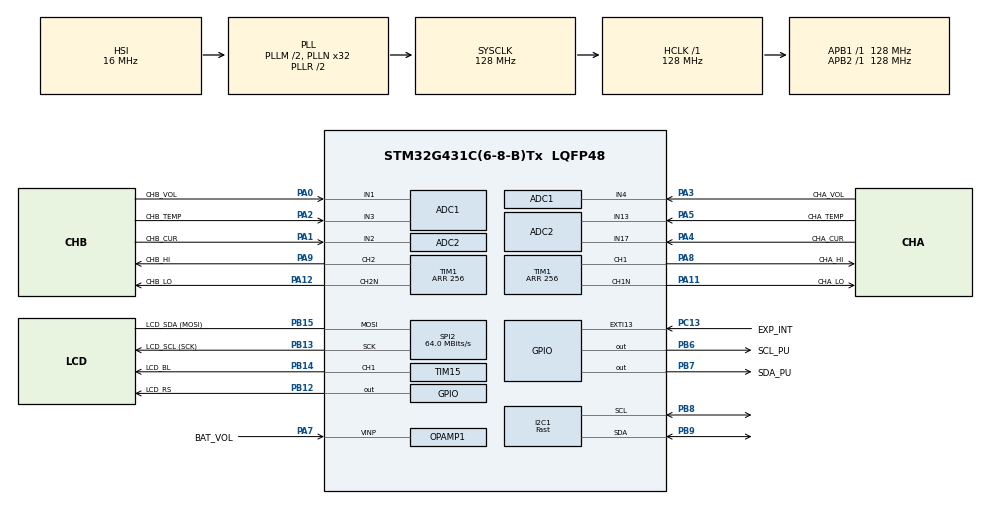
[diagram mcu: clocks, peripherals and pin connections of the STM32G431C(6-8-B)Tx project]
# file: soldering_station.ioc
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Mcu.Family=STM32G4
RCC.CortexFreq_Value=128000000
I2C1.I2C_Speed_Mode=I2C_Fast
ADC2.SamplingTime-1\#ChannelRegularConversion=ADC_SAMPLETIME_2CYCLES_5
SPI2.VirtualType=VM_MASTER
ADC1.ContinuousConvMode=ENABLE
ADC2.Channel-0\#ChannelRegularConversion=ADC_CHANNEL_17
Dma.ADC1.0.Polarity=HAL_DMAMUX_REQ_GEN_RISING
Dma.ADC2.1.SyncRequestNumber=1
PB14.GPIO_Label=LCD_BL
PA0.GPIO_Label=CHB_VOL
PA11.Mode=PWM Generation1 CH1 CH1N
Dma.I2C1_RX.2.MemDataAlignment=DMA_MDATAALIGN_BYTE
PB6.GPIO_Label=SCL_PU
PC13.GPIO_Label=EXP_INT
PB13.GPIO_Label=LCD_SCL (SCK)
PB13.Signal=SPI2_SCK
PB15.Signal=SPI2_MOSI
RCC.SYSCLKSource=RCC_SYSCLKSOURCE_PLLCLK
ProjectManager.StackSize=0x400
NVIC.DMA1_Channel3_IRQn=true\:0\:0\:false\:false\:true\:false\:true
PA12.Signal=TIM1_CH2N
PA4.Mode=IN17-Single-Ended
Dma.I2C1_RX.2.PeriphDataAlignment=DMA_PDATAALIGN_BYTE
ADC2.DMAContinuousRequests=ENABLE
ADC1.Mode=ADC_DUALMODE_REGSIMULT
ADC1.Channel-3\#ChannelRegularConversion=ADC_CHANNEL_1
Dma.ADC2.1.SyncEnable=DISABLE
RCC.HCLKFreq_Value=128000000
RCC.APB2TimFreq_Value=128000000
PB6.Signal=GPIO_Output
Dma.ADC1.0.Direction=DMA_PERIPH_TO_MEMORY
Dma.I2C1_RX.2.SyncPolarity=HAL_DMAMUX_SYNC_NO_EVENT
Dma.ADC1.0.MemDataAlignment=DMA_MDATAALIGN_HALFWORD
RCC.AHBFreq_Value=128000000
SPI2.BaudRatePrescaler=SPI_BAUDRATEPRESCALER_2
VREF+.Signal=VREFBUF_OUT
RCC.HSE_VALUE=8000000
PB3.Mode=JTAG_5_pins
PA15.Mode=JTAG_5_pins
RCC.ADC12Freq_Value=32000000
Dma.I2C1_RX.2.Mode=DMA_NORMAL
PB12.GPIO_Label=LCD_RS
Dma.ADC2.1.RequestNumber=1
Dma.ADC2.1.SyncPolarity=HAL_DMAMUX_SYNC_NO_EVENT
Dma.ADC2.1.Instance=DMA1_Channel2
PB4.Mode=JTAG_5_pins
PA14.Mode=JTAG_5_pins
Dma.ADC1.0.PeriphInc=DMA_PINC_DISABLE
TIM1.DeadTime=6
Dma.ADC2.1.Polarity=HAL_DMAMUX_REQ_GEN_RISING
NVIC.TIM2_IRQn=true\:0\:0\:false\:false\:true\:false\:true
PA0.Mode=IN1-Single-Ended
ADC2.DMAAccessModeView=DISABLED
PC13.GPIO_PuPd=GPIO_PULLUP
SPI2.CalculateBaudRate=64.0 MBits/s
VP_SYS_VS_DBSignals.Mode=DisableDeadBatterySignals
PB7.Signal=GPIO_Output
PA8.Signal=S_TIM1_CH1
Dma.ADC2.1.PeriphInc=DMA_PINC_DISABLE
Dma.I2C1_RX.2.Priority=DMA_PRIORITY_LOW
VREF+.GPIO_Label=VREF
VP_TIM1_VS_ClockSourceINT.Mode=Internal
PA0.Signal=ADC1_IN1
PB7.GPIO_Label=SDA_PU
Mcu.Package=LQFP48
PB9.Signal=I2C1_SDA
VP_SYS_VS_tim2.Mode=TIM2
NVIC.TimeBase=TIM2_IRQn
SPI2.Mode=SPI_MODE_MASTER
ADC1.OversamplingMode=DISABLE
Dma.I2C1_RX.2.PeriphInc=DMA_PINC_DISABLE
ADC2.Overrun=ADC_OVR_DATA_PRESERVED
Dma.I2C1_RX.2.Instance=DMA1_Channel3
PA2.GPIO_Label=CHB_TEMP
ADC2.Channel-1\#ChannelRegularConversion=ADC_CHANNEL_2
NVIC.TimeBaseIP=TIM2
PA15.Signal=SYS_JTDI
ADC1.OffsetNumber-1\#ChannelRegularConversion=ADC_OFFSET_NONE
ADC2.SamplingTime-0\#ChannelRegularConversion=ADC_SAMPLETIME_2CYCLES_5
Dma.I2C1_RX.2.MemInc=DMA_MINC_ENABLE
ADC2.NbrOfConversion=2
Dma.Request2=I2C1_RX
Dma.Request1=ADC2
RCC.APB1TimFreq_Value=128000000
SPI2.Direction=SPI_DIRECTION_1LINE
PB13.Mode=Simplex_Bidirectional_Master
ADC2.Rank-0\#ChannelRegularConversion=1
Dma.Request0=ADC1
PA4.GPIO_Label=CHA_CUR
Dma.ADC2.1.PeriphDataAlignment=DMA_PDATAALIGN_HALFWORD
Dma.ADC1.0.EventEnable=DISABLE
RCC.HSI48_VALUE=48000000
PB4.Signal=SYS_JTRST
TIM15.Channel-PWM\ Generation1\ CH1=TIM_CHANNEL_1
PA3.Signal=ADC1_IN4
PA5.Mode=IN13-Single-Ended
ADC2.ClockPrescaler=ADC_CLOCK_ASYNC_DIV1
VREF+.Mode=InternalMode
PB8-BOOT0.Mode=I2C
Dma.ADC1.0.Instance=DMA1_Channel1
ADC2.Mode=ADC_DUALMODE_REGSIMULT
PA7.Mode=Follower_Internally_Connected
Dma.ADC1.0.SyncRequestNumber=1
PC13.Signal=GPXTI13
PA9.GPIO_Label=CHB_HI
ADC1.OffsetNumber-3\#ChannelRegularConversion=ADC_OFFSET_NONE
PA11.GPIO_Label=CHA_LO
RCC.EXTERNAL_CLOCK_VALUE=12288000
TIM1.Channel-PWM\ Generation1\ CH1\ CH1N=TIM_CHANNEL_1
ADC2.EnableRegularConversion=ENABLE
PA12.GPIO_Label=CHB_LO
PA3.Mode=IN4-Single-Ended
PA13.Signal=SYS_JTMS-SWDIO
TIM1.Channel-PWM\ Generation2\ CH2\ CH2N=TIM_CHANNEL_2
Dma.ADC1.0.PeriphDataAlignment=DMA_PDATAALIGN_HALFWORD
Dma.ADC2.1.SyncSignalID=NONE
PA8.GPIO_Label=CHA_HI
SH.S_TIM1_CH1.0=TIM1_CH1,PWM Generation1 CH1 CH1N
ADC2.ContinuousConvMode=ENABLE
NVIC.DMA1_Channel2_IRQn=true\:0\:0\:false\:false\:true\:false\:true
ProjectManager.TargetToolchain=STM32CubeIDE
Dma.ADC1.0.Mode=DMA_CIRCULAR
Dma.ADC1.0.SignalID=NONE
Dma.ADC1.0.SyncSignalID=NONE
PB9.Mode=I2C
Dma.ADC1.0.Priority=DMA_PRIORITY_LOW
PA9.Signal=S_TIM1_CH2
ADC1.Channel-1\#ChannelRegularConversion=ADC_CHANNEL_4
I2C1.Timing=0x2040184B
RCC.USBFreq_Value=128000000
Dma.ADC2.1.Mode=DMA_CIRCULAR
RCC.LSE_VALUE=32768
ADC1.DMAAccessModeView=DISABLED
PA1.Signal=ADC2_IN2
ADC2.OffsetNumber-1\#ChannelRegularConversion=ADC_OFFSET_NONE
PB14.Signal=S_TIM15_CH1
PA5.Signal=ADC2_IN13
ADC2.OffsetNumber-0\#ChannelRegularConversion=ADC_OFFSET_NONE
PB8-BOOT0.Signal=I2C1_SCL
board=custom
Dma.I2C1_RX.2.SignalID=NONE
RCC.VCOOutputFreq_Value=256000000
SH.S_TIM15_CH1.0=TIM15_CH1,PWM Generation1 CH1
PB15.Mode=Simplex_Bidirectional_Master
Dma.I2C1_RX.2.SyncRequestNumber=1
Dma.I2C1_RX.2.SyncEnable=DISABLE
Dma.ADC1.0.SyncPolarity=HAL_DMAMUX_SYNC_NO_EVENT
RCC.APB2Freq_Value=128000000
PA1.Mode=IN2-Single-Ended
PB15.GPIO_Label=LCD_SDA (MOSI)
SH.S_TIM1_CH2.0=TIM1_CH2,PWM Generation2 CH2 CH2N
PA1.GPIO_Label=CHB_CUR
ADC1.DMAContinuousRequests=ENABLE
Dma.ADC2.1.MemInc=DMA_MINC_ENABLE
ADC1.NbrOfConversion=2
PA13.Mode=JTAG_5_pins
Mcu.Name=STM32G431C(6-8-B)Tx
PA2.Signal=ADC1_IN3
ADC2.EnableInjectedConversion=DISABLE
PB3.Signal=SYS_JTDO-SWO
PA4.Signal=ADC2_IN17
ADC1.SamplingTime-1\#ChannelRegularConversion=ADC_SAMPLETIME_2CYCLES_5
RCC.SYSCLKFreq_VALUE=128000000
Dma.ADC2.1.Direction=DMA_PERIPH_TO_MEMORY
PA7.GPIO_Label=BAT_VOL
ADC1.master=1
Dma.I2C1_RX.2.RequestNumber=1
PA12.Mode=PWM Generation2 CH2 CH2N
PA5.GPIO_Label=CHA_TEMP
ADC1.Rank-3\#ChannelRegularConversion=2
ADC1.SamplingTime-3\#ChannelRegularConversion=ADC_SAMPLETIME_2CYCLES_5
ADC2.NbrOfConversionFlag=1
PC13.GPIO_ModeDefaultEXTI=GPIO_MODE_IT_FALLING
Dma.I2C1_RX.2.Polarity=HAL_DMAMUX_REQ_GEN_RISING
RCC.ADC12CLockSelection=RCC_ADC12CLKSOURCE_PLL
ADC1.Rank-1\#ChannelRegularConversion=1
Dma.ADC1.0.RequestNumber=1
PA11.Signal=TIM1_CH1N
VP_TIM15_VS_ClockSourceINT.Mode=Internal
Dma.ADC1.0.SyncEnable=DISABLE
PA14.Signal=SYS_JTCK-SWCLK
Dma.ADC1.0.MemInc=DMA_MINC_ENABLE
ProjectManager.HeapSize=0x200
ADC2.OversamplingMode=DISABLE
Dma.I2C1_RX.2.SyncSignalID=NONE
Dma.ADC2.1.SignalID=NONE
RCC.HSI_VALUE=16000000
Dma.ADC2.1.EventEnable=DISABLE
RCC.PLLP=RCC_PLLP_DIV8
NVIC.PriorityGroup=NVIC_PRIORITYGROUP_4
ADC1.NbrOfConversionFlag=1
Dma.ADC2.1.MemDataAlignment=DMA_MDATAALIGN_HALFWORD
RCC.PLLM=RCC_PLLM_DIV2
RCC.PLLN=32
ADC2.Rank-1\#ChannelRegularConversion=2
ADC1.EnableRegularConversion=ENABLE
PA2.Mode=IN3-Single-Ended
Dma.ADC2.1.Priority=DMA_PRIORITY_LOW
NVIC.DMA1_Channel1_IRQn=true\:0\:0\:false\:false\:true\:false\:true
Dma.I2C1_RX.2.EventEnable=DISABLE
RCC.APB1Freq_Value=128000000
ADC1.ClockPrescaler=ADC_CLOCK_ASYNC_DIV1
PB12.Signal=GPIO_Output
TIM1.PeriodNoDither=256
Dma.I2C1_RX.2.Direction=DMA_PERIPH_TO_MEMORY
PA3.GPIO_Label=CHA_VOL
PA7.Signal=OPAMP1_VINP

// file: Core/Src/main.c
/* USER CODE BEGIN Header */
/**
  ******************************************************************************
  * @file           : main.c
  * @brief          : Main program body
  ******************************************************************************
  * @attention
  *
  * <h2><center>&copy; Copyright (c) 2021 STMicroelectronics.
  * All rights reserved.</center></h2>
  *
  * This software component is licensed by ST under BSD 3-Clause license,
  * the "License"; You may not use this file except in compliance with the
  * License. You may obtain a copy of the License at:
  *                        opensource.org/licenses/BSD-3-Clause
  *
  ******************************************************************************
  */
/* USER CODE END Header */
#include "main.h"

/* USER CODE BEGIN Includes */
#include "entrypoint.h"
/* USER CODE END Includes */

ADC_HandleTypeDef hadc1;
ADC_HandleTypeDef hadc2;
DMA_HandleTypeDef hdma_adc1;
DMA_HandleTypeDef hdma_adc2;

I2C_HandleTypeDef hi2c1;
DMA_HandleTypeDef hdma_i2c1_rx;

OPAMP_HandleTypeDef hopamp1;

SPI_HandleTypeDef hspi2;

TIM_HandleTypeDef htim1;
TIM_HandleTypeDef htim15;

void SystemClock_Config(void);
static void MX_GPIO_Init(void);
static void MX_DMA_Init(void);
static void MX_ADC1_Init(void);
static void MX_ADC2_Init(void);
static void MX_I2C1_Init(void);
static void MX_TIM1_Init(void);
static void MX_SPI2_Init(void);
static void MX_TIM15_Init(void);
static void MX_OPAMP1_Init(void);

int main(void)
{

  /* MCU Configuration--------------------------------------------------------*/

  /* Reset of all peripherals, Initializes the Flash interface and the Systick. */
  HAL_Init();

  /* Configure the system clock */
  SystemClock_Config();

  /* Initialize all configured peripherals */
  MX_GPIO_Init();
  MX_DMA_Init();
  MX_ADC1_Init();
  MX_ADC2_Init();
  MX_I2C1_Init();
  MX_TIM1_Init();
  MX_SPI2_Init();
  MX_TIM15_Init();
  MX_OPAMP1_Init();
  /* USER CODE BEGIN 2 */
  entrypoint_go();
  /* USER CODE END 2 */

  /* Infinite loop */
  while (1)
  {

  }
}

void SystemClock_Config(void)
{
  RCC_OscInitTypeDef RCC_OscInitStruct = {0};
  RCC_ClkInitTypeDef RCC_ClkInitStruct = {0};
  RCC_PeriphCLKInitTypeDef PeriphClkInit = {0};

  /** Configure the main internal regulator output voltage
  */
  HAL_PWREx_ControlVoltageScaling(PWR_REGULATOR_VOLTAGE_SCALE1);
  /** Initializes the RCC Oscillators according to the specified parameters
  * in the RCC_OscInitTypeDef structure.
  */
  RCC_OscInitStruct.OscillatorType = RCC_OSCILLATORTYPE_HSI;
  RCC_OscInitStruct.HSIState = RCC_HSI_ON;
  RCC_OscInitStruct.HSICalibrationValue = RCC_HSICALIBRATION_DEFAULT;
  RCC_OscInitStruct.PLL.PLLState = RCC_PLL_ON;
  RCC_OscInitStruct.PLL.PLLSource = RCC_PLLSOURCE_HSI;
  RCC_OscInitStruct.PLL.PLLM = RCC_PLLM_DIV2;
  RCC_OscInitStruct.PLL.PLLN = 32;
  RCC_OscInitStruct.PLL.PLLP = RCC_PLLP_DIV8;
  RCC_OscInitStruct.PLL.PLLQ = RCC_PLLQ_DIV2;
  RCC_OscInitStruct.PLL.PLLR = RCC_PLLR_DIV2;
  if (HAL_RCC_OscConfig(&RCC_OscInitStruct) != HAL_OK)
  {
    Error_Handler();
  }
  /** Initializes the CPU, AHB and APB buses clocks
  */
  RCC_ClkInitStruct.ClockType = RCC_CLOCKTYPE_HCLK|RCC_CLOCKTYPE_SYSCLK
                              |RCC_CLOCKTYPE_PCLK1|RCC_CLOCKTYPE_PCLK2;
  RCC_ClkInitStruct.SYSCLKSource = RCC_SYSCLKSOURCE_PLLCLK;
  RCC_ClkInitStruct.AHBCLKDivider = RCC_SYSCLK_DIV1;
  RCC_ClkInitStruct.APB1CLKDivider = RCC_HCLK_DIV1;
  RCC_ClkInitStruct.APB2CLKDivider = RCC_HCLK_DIV1;

  if (HAL_RCC_ClockConfig(&RCC_ClkInitStruct, FLASH_LATENCY_3) != HAL_OK)
  {
    Error_Handler();
  }
  /** Initializes the peripherals clocks
  */
  PeriphClkInit.PeriphClockSelection = RCC_PERIPHCLK_I2C1|RCC_PERIPHCLK_ADC12;
  PeriphClkInit.I2c1ClockSelection = RCC_I2C1CLKSOURCE_PCLK1;
  PeriphClkInit.Adc12ClockSelection = RCC_ADC12CLKSOURCE_PLL;
  if (HAL_RCCEx_PeriphCLKConfig(&PeriphClkInit) != HAL_OK)
  {
    Error_Handler();
  }
}

static void MX_ADC1_Init(void)
{

  ADC_MultiModeTypeDef multimode = {0};
  ADC_ChannelConfTypeDef sConfig = {0};

  /** Common config
  */
  hadc1.Instance = ADC1;
  hadc1.Init.ClockPrescaler = ADC_CLOCK_ASYNC_DIV1;
  hadc1.Init.Resolution = ADC_RESOLUTION_12B;
  hadc1.Init.DataAlign = ADC_DATAALIGN_RIGHT;
  hadc1.Init.GainCompensation = 0;
  hadc1.Init.ScanConvMode = ADC_SCAN_ENABLE;
  hadc1.Init.EOCSelection = ADC_EOC_SINGLE_CONV;
  hadc1.Init.LowPowerAutoWait = DISABLE;
  hadc1.Init.ContinuousConvMode = ENABLE;
  hadc1.Init.NbrOfConversion = 2;
  hadc1.Init.DiscontinuousConvMode = DISABLE;
  hadc1.Init.ExternalTrigConv = ADC_SOFTWARE_START;
  hadc1.Init.ExternalTrigConvEdge = ADC_EXTERNALTRIGCONVEDGE_NONE;
  hadc1.Init.DMAContinuousRequests = ENABLE;
  hadc1.Init.Overrun = ADC_OVR_DATA_PRESERVED;
  hadc1.Init.OversamplingMode = DISABLE;
  if (HAL_ADC_Init(&hadc1) != HAL_OK)
  {
    Error_Handler();
  }
  /** Configure the ADC multi-mode
  */
  multimode.Mode = ADC_DUALMODE_REGSIMULT;
  multimode.DMAAccessMode = ADC_DMAACCESSMODE_DISABLED;
  multimode.TwoSamplingDelay = ADC_TWOSAMPLINGDELAY_1CYCLE;
  if (HAL_ADCEx_MultiModeConfigChannel(&hadc1, &multimode) != HAL_OK)
  {
    Error_Handler();
  }
  /** Configure Regular Channel
  */
  sConfig.Channel = ADC_CHANNEL_4;
  sConfig.Rank = ADC_REGULAR_RANK_1;
  sConfig.SamplingTime = ADC_SAMPLETIME_2CYCLES_5;
  sConfig.SingleDiff = ADC_SINGLE_ENDED;
  sConfig.OffsetNumber = ADC_OFFSET_NONE;
  sConfig.Offset = 0;
  if (HAL_ADC_ConfigChannel(&hadc1, &sConfig) != HAL_OK)
  {
    Error_Handler();
  }
  /** Configure Regular Channel
  */
  sConfig.Channel = ADC_CHANNEL_1;
  sConfig.Rank = ADC_REGULAR_RANK_2;
  if (HAL_ADC_ConfigChannel(&hadc1, &sConfig) != HAL_OK)
  {
    Error_Handler();
  }

}

static void MX_ADC2_Init(void)
{

  ADC_ChannelConfTypeDef sConfig = {0};

  /** Common config
  */
  hadc2.Instance = ADC2;
  hadc2.Init.ClockPrescaler = ADC_CLOCK_ASYNC_DIV1;
  hadc2.Init.Resolution = ADC_RESOLUTION_12B;
  hadc2.Init.DataAlign = ADC_DATAALIGN_RIGHT;
  hadc2.Init.GainCompensation = 0;
  hadc2.Init.ScanConvMode = ADC_SCAN_ENABLE;
  hadc2.Init.EOCSelection = ADC_EOC_SINGLE_CONV;
  hadc2.Init.LowPowerAutoWait = DISABLE;
  hadc2.Init.ContinuousConvMode = ENABLE;
  hadc2.Init.NbrOfConversion = 2;
  hadc2.Init.DiscontinuousConvMode = DISABLE;
  hadc2.Init.DMAContinuousRequests = ENABLE;
  hadc2.Init.Overrun = ADC_OVR_DATA_PRESERVED;
  hadc2.Init.OversamplingMode = DISABLE;
  if (HAL_ADC_Init(&hadc2) != HAL_OK)
  {
    Error_Handler();
  }
  /** Configure Regular Channel
  */
  sConfig.Channel = ADC_CHANNEL_17;
  sConfig.Rank = ADC_REGULAR_RANK_1;
  sConfig.SamplingTime = ADC_SAMPLETIME_2CYCLES_5;
  sConfig.SingleDiff = ADC_SINGLE_ENDED;
  sConfig.OffsetNumber = ADC_OFFSET_NONE;
  sConfig.Offset = 0;
  if (HAL_ADC_ConfigChannel(&hadc2, &sConfig) != HAL_OK)
  {
    Error_Handler();
  }
  /** Configure Regular Channel
  */
  sConfig.Channel = ADC_CHANNEL_2;
  sConfig.Rank = ADC_REGULAR_RANK_2;
  if (HAL_ADC_ConfigChannel(&hadc2, &sConfig) != HAL_OK)
  {
    Error_Handler();
  }

}

static void MX_I2C1_Init(void)
{

  hi2c1.Instance = I2C1;
  hi2c1.Init.Timing = 0x2040184B;
  hi2c1.Init.OwnAddress1 = 0;
  hi2c1.Init.AddressingMode = I2C_ADDRESSINGMODE_7BIT;
  hi2c1.Init.DualAddressMode = I2C_DUALADDRESS_DISABLE;
  hi2c1.Init.OwnAddress2 = 0;
  hi2c1.Init.OwnAddress2Masks = I2C_OA2_NOMASK;
  hi2c1.Init.GeneralCallMode = I2C_GENERALCALL_DISABLE;
  hi2c1.Init.NoStretchMode = I2C_NOSTRETCH_DISABLE;
  if (HAL_I2C_Init(&hi2c1) != HAL_OK)
  {
    Error_Handler();
  }
  /** Configure Analogue filter
  */
  if (HAL_I2CEx_ConfigAnalogFilter(&hi2c1, I2C_ANALOGFILTER_ENABLE) != HAL_OK)
  {
    Error_Handler();
  }
  /** Configure Digital filter
  */
  if (HAL_I2CEx_ConfigDigitalFilter(&hi2c1, 0) != HAL_OK)
  {
    Error_Handler();
  }

}

static void MX_OPAMP1_Init(void)
{

  hopamp1.Instance = OPAMP1;
  hopamp1.Init.PowerMode = OPAMP_POWERMODE_NORMALSPEED;
  hopamp1.Init.Mode = OPAMP_FOLLOWER_MODE;
  hopamp1.Init.NonInvertingInput = OPAMP_NONINVERTINGINPUT_IO2;
  hopamp1.Init.InternalOutput = ENABLE;
  hopamp1.Init.TimerControlledMuxmode = OPAMP_TIMERCONTROLLEDMUXMODE_DISABLE;
  hopamp1.Init.UserTrimming = OPAMP_TRIMMING_FACTORY;
  if (HAL_OPAMP_Init(&hopamp1) != HAL_OK)
  {
    Error_Handler();
  }

}

static void MX_SPI2_Init(void)
{

  /* SPI2 parameter configuration*/
  hspi2.Instance = SPI2;
  hspi2.Init.Mode = SPI_MODE_MASTER;
  hspi2.Init.Direction = SPI_DIRECTION_1LINE;
  hspi2.Init.DataSize = SPI_DATASIZE_4BIT;
  hspi2.Init.CLKPolarity = SPI_POLARITY_LOW;
  hspi2.Init.CLKPhase = SPI_PHASE_1EDGE;
  hspi2.Init.NSS = SPI_NSS_SOFT;
  hspi2.Init.BaudRatePrescaler = SPI_BAUDRATEPRESCALER_2;
  hspi2.Init.FirstBit = SPI_FIRSTBIT_MSB;
  hspi2.Init.TIMode = SPI_TIMODE_DISABLE;
  hspi2.Init.CRCCalculation = SPI_CRCCALCULATION_DISABLE;
  hspi2.Init.CRCPolynomial = 7;
  hspi2.Init.CRCLength = SPI_CRC_LENGTH_DATASIZE;
  hspi2.Init.NSSPMode = SPI_NSS_PULSE_ENABLE;
  if (HAL_SPI_Init(&hspi2) != HAL_OK)
  {
    Error_Handler();
  }

}

static void MX_TIM1_Init(void)
{

  TIM_ClockConfigTypeDef sClockSourceConfig = {0};
  TIM_MasterConfigTypeDef sMasterConfig = {0};
  TIM_OC_InitTypeDef sConfigOC = {0};
  TIM_BreakDeadTimeConfigTypeDef sBreakDeadTimeConfig = {0};

  htim1.Instance = TIM1;
  htim1.Init.Prescaler = 0;
  htim1.Init.CounterMode = TIM_COUNTERMODE_UP;
  htim1.Init.Period = 256;
  htim1.Init.ClockDivision = TIM_CLOCKDIVISION_DIV1;
  htim1.Init.RepetitionCounter = 0;
  htim1.Init.AutoReloadPreload = TIM_AUTORELOAD_PRELOAD_DISABLE;
  if (HAL_TIM_Base_Init(&htim1) != HAL_OK)
  {
    Error_Handler();
  }
  sClockSourceConfig.ClockSource = TIM_CLOCKSOURCE_INTERNAL;
  if (HAL_TIM_ConfigClockSource(&htim1, &sClockSourceConfig) != HAL_OK)
  {
    Error_Handler();
  }
  if (HAL_TIM_PWM_Init(&htim1) != HAL_OK)
  {
    Error_Handler();
  }
  sMasterConfig.MasterOutputTrigger = TIM_TRGO_RESET;
  sMasterConfig.MasterOutputTrigger2 = TIM_TRGO2_RESET;
  sMasterConfig.MasterSlaveMode = TIM_MASTERSLAVEMODE_DISABLE;
  if (HAL_TIMEx_MasterConfigSynchronization(&htim1, &sMasterConfig) != HAL_OK)
  {
    Error_Handler();
  }
  sConfigOC.OCMode = TIM_OCMODE_PWM1;
  sConfigOC.Pulse = 0;
  sConfigOC.OCPolarity = TIM_OCPOLARITY_HIGH;
  sConfigOC.OCNPolarity = TIM_OCNPOLARITY_HIGH;
  sConfigOC.OCFastMode = TIM_OCFAST_DISABLE;
  sConfigOC.OCIdleState = TIM_OCIDLESTATE_RESET;
  sConfigOC.OCNIdleState = TIM_OCNIDLESTATE_RESET;
  if (HAL_TIM_PWM_ConfigChannel(&htim1, &sConfigOC, TIM_CHANNEL_1) != HAL_OK)
  {
    Error_Handler();
  }
  if (HAL_TIM_PWM_ConfigChannel(&htim1, &sConfigOC, TIM_CHANNEL_2) != HAL_OK)
  {
    Error_Handler();
  }
  sBreakDeadTimeConfig.OffStateRunMode = TIM_OSSR_DISABLE;
  sBreakDeadTimeConfig.OffStateIDLEMode = TIM_OSSI_DISABLE;
  sBreakDeadTimeConfig.LockLevel = TIM_LOCKLEVEL_OFF;
  sBreakDeadTimeConfig.DeadTime = 6;
  sBreakDeadTimeConfig.BreakState = TIM_BREAK_DISABLE;
  sBreakDeadTimeConfig.BreakPolarity = TIM_BREAKPOLARITY_HIGH;
  sBreakDeadTimeConfig.BreakFilter = 0;
  sBreakDeadTimeConfig.BreakAFMode = TIM_BREAK_AFMODE_INPUT;
  sBreakDeadTimeConfig.Break2State = TIM_BREAK2_DISABLE;
  sBreakDeadTimeConfig.Break2Polarity = TIM_BREAK2POLARITY_HIGH;
  sBreakDeadTimeConfig.Break2Filter = 0;
  sBreakDeadTimeConfig.Break2AFMode = TIM_BREAK_AFMODE_INPUT;
  sBreakDeadTimeConfig.AutomaticOutput = TIM_AUTOMATICOUTPUT_DISABLE;
  if (HAL_TIMEx_ConfigBreakDeadTime(&htim1, &sBreakDeadTimeConfig) != HAL_OK)
  {
    Error_Handler();
  }
  HAL_TIM_MspPostInit(&htim1);

}

static void MX_TIM15_Init(void)
{

  TIM_ClockConfigTypeDef sClockSourceConfig = {0};
  TIM_MasterConfigTypeDef sMasterConfig = {0};
  TIM_OC_InitTypeDef sConfigOC = {0};
  TIM_BreakDeadTimeConfigTypeDef sBreakDeadTimeConfig = {0};

  htim15.Instance = TIM15;
  htim15.Init.Prescaler = 0;
  htim15.Init.CounterMode = TIM_COUNTERMODE_UP;
  htim15.Init.Period = 65535;
  htim15.Init.ClockDivision = TIM_CLOCKDIVISION_DIV1;
  htim15.Init.RepetitionCounter = 0;
  htim15.Init.AutoReloadPreload = TIM_AUTORELOAD_PRELOAD_DISABLE;
  if (HAL_TIM_Base_Init(&htim15) != HAL_OK)
  {
    Error_Handler();
  }
  sClockSourceConfig.ClockSource = TIM_CLOCKSOURCE_INTERNAL;
  if (HAL_TIM_ConfigClockSource(&htim15, &sClockSourceConfig) != HAL_OK)
  {
    Error_Handler();
  }
  if (HAL_TIM_PWM_Init(&htim15) != HAL_OK)
  {
    Error_Handler();
  }
  sMasterConfig.MasterOutputTrigger = TIM_TRGO_RESET;
  sMasterConfig.MasterSlaveMode = TIM_MASTERSLAVEMODE_DISABLE;
  if (HAL_TIMEx_MasterConfigSynchronization(&htim15, &sMasterConfig) != HAL_OK)
  {
    Error_Handler();
  }
  sConfigOC.OCMode = TIM_OCMODE_PWM1;
  sConfigOC.Pulse = 0;
  sConfigOC.OCPolarity = TIM_OCPOLARITY_HIGH;
  sConfigOC.OCNPolarity = TIM_OCNPOLARITY_HIGH;
  sConfigOC.OCFastMode = TIM_OCFAST_DISABLE;
  sConfigOC.OCIdleState = TIM_OCIDLESTATE_RESET;
  sConfigOC.OCNIdleState = TIM_OCNIDLESTATE_RESET;
  if (HAL_TIM_PWM_ConfigChannel(&htim15, &sConfigOC, TIM_CHANNEL_1) != HAL_OK)
  {
    Error_Handler();
  }
  sBreakDeadTimeConfig.OffStateRunMode = TIM_OSSR_DISABLE;
  sBreakDeadTimeConfig.OffStateIDLEMode = TIM_OSSI_DISABLE;
  sBreakDeadTimeConfig.LockLevel = TIM_LOCKLEVEL_OFF;
  sBreakDeadTimeConfig.DeadTime = 0;
  sBreakDeadTimeConfig.BreakState = TIM_BREAK_DISABLE;
  sBreakDeadTimeConfig.BreakPolarity = TIM_BREAKPOLARITY_HIGH;
  sBreakDeadTimeConfig.BreakFilter = 0;
  sBreakDeadTimeConfig.AutomaticOutput = TIM_AUTOMATICOUTPUT_DISABLE;
  if (HAL_TIMEx_ConfigBreakDeadTime(&htim15, &sBreakDeadTimeConfig) != HAL_OK)
  {
    Error_Handler();
  }
  HAL_TIM_MspPostInit(&htim15);

}

static void MX_DMA_Init(void)
{

  /* DMA controller clock enable */
  __HAL_RCC_DMAMUX1_CLK_ENABLE();
  __HAL_RCC_DMA1_CLK_ENABLE();

  /* DMA interrupt init */
  /* DMA1_Channel1_IRQn interrupt configuration */
  HAL_NVIC_SetPriority(DMA1_Channel1_IRQn, 0, 0);
  HAL_NVIC_EnableIRQ(DMA1_Channel1_IRQn);
  /* DMA1_Channel2_IRQn interrupt configuration */
  HAL_NVIC_SetPriority(DMA1_Channel2_IRQn, 0, 0);
  HAL_NVIC_EnableIRQ(DMA1_Channel2_IRQn);
  /* DMA1_Channel3_IRQn interrupt configuration */
  HAL_NVIC_SetPriority(DMA1_Channel3_IRQn, 0, 0);
  HAL_NVIC_EnableIRQ(DMA1_Channel3_IRQn);

}

static void MX_GPIO_Init(void)
{
  GPIO_InitTypeDef GPIO_InitStruct = {0};

  /* GPIO Ports Clock Enable */
  __HAL_RCC_GPIOC_CLK_ENABLE();
  __HAL_RCC_GPIOA_CLK_ENABLE();
  __HAL_RCC_GPIOB_CLK_ENABLE();

  /*Configure GPIO pin Output Level */
  HAL_GPIO_WritePin(GPIOB, LCD_RS_Pin|SCL_PU_Pin|SDA_PU_Pin, GPIO_PIN_RESET);

  /*Configure GPIO pin : EXP_INT_Pin */
  GPIO_InitStruct.Pin = EXP_INT_Pin;
  GPIO_InitStruct.Mode = GPIO_MODE_IT_FALLING;
  GPIO_InitStruct.Pull = GPIO_PULLUP;
  HAL_GPIO_Init(EXP_INT_GPIO_Port, &GPIO_InitStruct);

  /*Configure GPIO pins : LCD_RS_Pin SCL_PU_Pin SDA_PU_Pin */
  GPIO_InitStruct.Pin = LCD_RS_Pin|SCL_PU_Pin|SDA_PU_Pin;
  GPIO_InitStruct.Mode = GPIO_MODE_OUTPUT_PP;
  GPIO_InitStruct.Pull = GPIO_NOPULL;
  GPIO_InitStruct.Speed = GPIO_SPEED_FREQ_LOW;
  HAL_GPIO_Init(GPIOB, &GPIO_InitStruct);

}

 /**
  * @brief  Period elapsed callback in non blocking mode
  * @note   This function is called  when TIM2 interrupt took place, inside
  * HAL_TIM_IRQHandler(). It makes a direct call to HAL_IncTick() to increment
  * a global variable "uwTick" used as application time base.
  * @param  htim : TIM handle
  * @retval None
  */
void HAL_TIM_PeriodElapsedCallback(TIM_HandleTypeDef *htim)
{
  if (htim->Instance == TIM2) {
    HAL_IncTick();
  }
}

void Error_Handler(void)
{
  __disable_irq();
  while (1)
  {
  }
}

/************************ (C) COPYRIGHT STMicroelectronics *****END OF FILE****/
